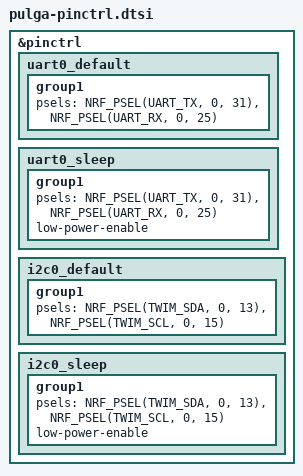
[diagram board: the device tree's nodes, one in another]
&pinctrl {
	uart0_default: uart0_default {
		group1 {
			psels = <NRF_PSEL(UART_TX, 0, 31)>,
					<NRF_PSEL(UART_RX, 0, 25)>;
		};
	};

	uart0_sleep: uart0_sleep {
		group1 {
			psels = <NRF_PSEL(UART_TX, 0, 31)>,
					<NRF_PSEL(UART_RX, 0, 25)>;
			low-power-enable;
		};
	};

	i2c0_default: i2c0_default {
		group1 {
			psels = <NRF_PSEL(TWIM_SDA, 0, 13)>,
					<NRF_PSEL(TWIM_SCL, 0, 15)>;
		};
	};

	i2c0_sleep: i2c0_sleep {
		group1 {
			psels = <NRF_PSEL(TWIM_SDA, 0, 13)>,
					<NRF_PSEL(TWIM_SCL, 0, 15)>;
			low-power-enable;
		};
	};
};
